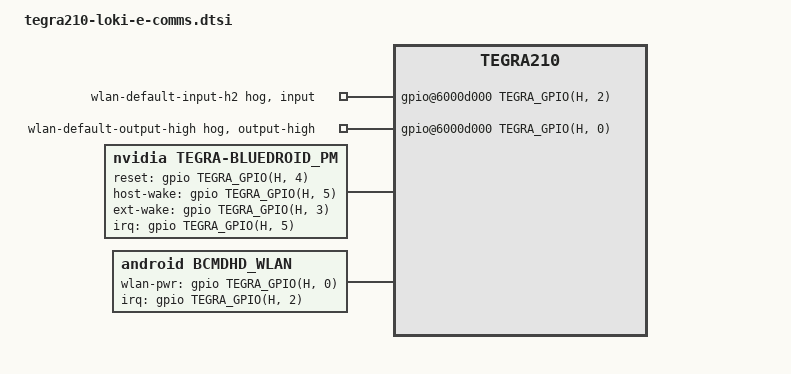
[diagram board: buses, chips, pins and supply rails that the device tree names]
#include <dt-bindings/gpio/tegra-gpio.h>

/ {
	gpio@6000d000 {
		wlan-default-input {
			gpio-hog;
			input;
			gpios = <
				TEGRA_GPIO(H, 2) 0
				>;
			label = "wlan-default-input-h2";
		};

		wlan-default-output-high {
			gpio-hog;
			output-high;
			gpios = <
				TEGRA_GPIO(H, 0) 0
				>;
			label = "wlan-default-output-high";
		};
	};

	bluedroid_pm {
		compatible = "nvidia,tegra-bluedroid_pm";
		id = <0>;
		bluedroid_pm,reset-gpio = <&gpio TEGRA_GPIO(H, 4) 0>;
		bluedroid_pm,host-wake-gpio = <&gpio TEGRA_GPIO(H, 5) 0>;
		bluedroid_pm,ext-wake-gpio = <&gpio TEGRA_GPIO(H, 3) 0>;
		interrupt-parent = <&gpio>;
		interrupts = <TEGRA_GPIO(H, 5) 0x01>;
	};

	bcmdhd_wlan {
		compatible = "android,bcmdhd_wlan";
		interrupt-parent = <&gpio>;
		interrupts = <TEGRA_GPIO(H, 2) 0x14>;
		wlan-pwr-gpio = <&gpio TEGRA_GPIO(H, 0) 0>;
		status = "okay";
	};

	bcm4329_wlan2_ {
		compatible = "nvidia,tegra-bcmdhd2-wlan";
		interrupt-parent = <&gpio>;
		interrupts = <TEGRA_GPIO(I, 1) 0x14>;
		wlan-pwr-gpio = <&gpio TEGRA_GPIO(I, 0) 0>;
/*
		wlan-rst-gpio = <&gpio TEGRA_GPIO(I, xxx) 0>;
*/
		status = "disabled";
	};
};
